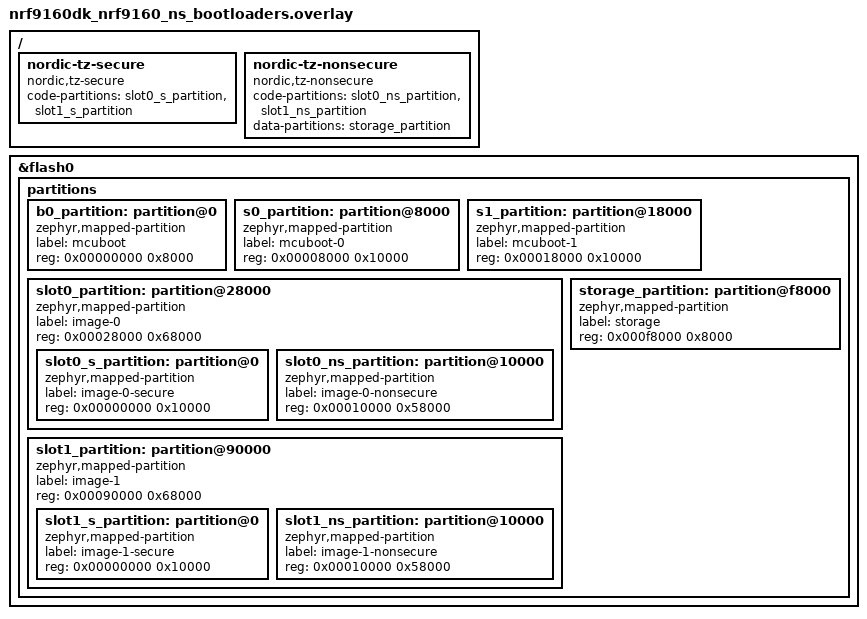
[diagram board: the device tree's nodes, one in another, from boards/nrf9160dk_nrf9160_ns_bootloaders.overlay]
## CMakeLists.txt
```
#
# Copyright (c) 2020 Nordic Semiconductor ASA
#
# SPDX-License-Identifier: LicenseRef-Nordic-5-Clause
#

cmake_minimum_required(VERSION 3.20.0)

find_package(Zephyr REQUIRED HINTS $ENV{ZEPHYR_BASE})

project(tfm_hello_world)

# NORDIC SDK APP START
target_sources(app PRIVATE src/main.c)
# NORDIC SDK APP END
```

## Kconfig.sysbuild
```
#
# Copyright (c) 2026 Nordic Semiconductor
#
# SPDX-License-Identifier: LicenseRef-Nordic-5-Clause
#

config PARTITION_MANAGER
	default n if !SOC_SERIES_NRF91 && !SOC_SERIES_NRF53

source "share/sysbuild/Kconfig"
```

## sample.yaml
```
sample:
  description: Hello World sample, the simplest Zephyr application, with TF-M enabled
  name: TF-M Hello World sample
common:
  tags:
    - tfm
    - ci_samples_tfm
  platform_allow:
    - nrf5340dk/nrf5340/cpuapp/ns
    - nrf9151dk/nrf9151/ns
    - nrf9160dk/nrf9160/ns
    - nrf9161dk/nrf9161/ns
  integration_platforms:
    - nrf5340dk/nrf5340/cpuapp/ns
    - nrf9151dk/nrf9151/ns
    - nrf9160dk/nrf9160/ns
    - nrf9161dk/nrf9161/ns
  harness: console
  harness_config:
    type: multi_line
    regex:
      - ".*Example finished successfully!.*"
tests:
  sample.tfm.helloworld:
    sysbuild: true
    tags:
      - ci_build
      - sysbuild
      - ci_samples_tfm
    platform_allow:
      - nrf54l15dk/nrf54l15/cpuapp/ns
      - nrf54lc10dk/nrf54lc10a/cpuapp/ns
      - nrf54lv10dk/nrf54lv10a/cpuapp/ns
      - nrf54lm20dk/nrf54lm20a/cpuapp/ns
      - nrf54lm20dk/nrf54lm20b/cpuapp/ns
      - nrf7120dk/nrf7120/cpuapp/ns
    integration_platforms:
      - nrf54l15dk/nrf54l15/cpuapp/ns
      - nrf54lc10dk/nrf54lc10a/cpuapp/ns
      - nrf54lv10dk/nrf54lv10a/cpuapp/ns
      - nrf54lm20dk/nrf54lm20a/cpuapp/ns
      - nrf54lm20dk/nrf54lm20b/cpuapp/ns
      - nrf7120dk/nrf7120/cpuapp/ns
  sample.tfm.hello_world.bootloaders:
    sysbuild: true
    tags:
      - ci_build
      - sysbuild
      - ci_samples_tfm
    extra_args: FILE_SUFFIX=bootloaders
  sample.tfm.hello_world.bootloaders_debug:
    sysbuild: true
    build_only: true
    tags:
      - ci_build
      - sysbuild
      - ci_samples_tfm
    extra_args:
      - FILE_SUFFIX=bootloaders
      - CONFIG_DEBUG_OPTIMIZATIONS=y
      - CONFIG_TFM_CMAKE_BUILD_TYPE_MINSIZEREL=y
  sample.tfm.hello_world.full:
    sysbuild: true
    tags:
      - ci_build
      - sysbuild
      - ci_samples_tfm
    extra_args:
      - CONFIG_TFM_PROFILE_TYPE_NOT_SET=y
    platform_allow:
      - nrf54l15dk/nrf54l15/cpuapp/ns
      - nrf54lc10dk/nrf54lc10a/cpuapp/ns
      - nrf54lv10dk/nrf54lv10a/cpuapp/ns
      - nrf54lm20dk/nrf54lm20a/cpuapp/ns
      - nrf54lm20dk/nrf54lm20b/cpuapp/ns
    integration_platforms:
      - nrf54l15dk/nrf54l15/cpuapp/ns
      - nrf54lc10dk/nrf54lc10a/cpuapp/ns
      - nrf54lv10dk/nrf54lv10a/cpuapp/ns
      - nrf54lm20dk/nrf54lm20a/cpuapp/ns
      - nrf54lm20dk/nrf54lm20b/cpuapp/ns
  sample.tfm.hello_world.lvl2:
    sysbuild: true
    tags:
      - ci_build
      - sysbuild
      - ci_samples_tfm
    extra_args:
      - CONFIG_TFM_IPC=y
      - CONFIG_TFM_ISOLATION_LEVEL=2
      - CONFIG_TFM_PROFILE_TYPE_NOT_SET=y
    platform_allow:
      - nrf54l15dk/nrf54l15/cpuapp/ns
      - nrf54lc10dk/nrf54lc10a/cpuapp/ns
      - nrf54lv10dk/nrf54lv10a/cpuapp/ns
      - nrf54lm20dk/nrf54lm20a/cpuapp/ns
      - nrf54lm20dk/nrf54lm20b/cpuapp/ns
    integration_platforms:
      - nrf54l15dk/nrf54l15/cpuapp/ns
      - nrf54lc10dk/nrf54lc10a/cpuapp/ns
      - nrf54lv10dk/nrf54lv10a/cpuapp/ns
      - nrf54lm20dk/nrf54lm20a/cpuapp/ns
      - nrf54lm20dk/nrf54lm20b/cpuapp/ns
```

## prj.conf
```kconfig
#
# Copyright (c) 2020 Nordic Semiconductor ASA
#
# SPDX-License-Identifier: LicenseRef-Nordic-5-Clause
#

CONFIG_TFM_PROFILE_TYPE_MINIMAL=y
CONFIG_PSA_WANT_GENERATE_RANDOM=y
```

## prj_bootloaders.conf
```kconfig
#
# Copyright (c) 2020 Nordic Semiconductor ASA
#
# SPDX-License-Identifier: LicenseRef-Nordic-5-Clause
#

CONFIG_TFM_PROFILE_TYPE_MINIMAL=y
CONFIG_PSA_WANT_GENERATE_RANDOM=y
CONFIG_FW_INFO=y
```

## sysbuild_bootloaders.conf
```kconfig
#
# Copyright (c) 2024 Nordic Semiconductor ASA
#
# SPDX-License-Identifier: LicenseRef-Nordic-5-Clause
#

SB_CONFIG_BOOTLOADER_MCUBOOT=y
SB_CONFIG_SECURE_BOOT_APPCORE=y
# Ineffective here: unsatisfied dependency (!SECURE_BOOT_APPCORE), so
# MCUBOOT_HARDWARE_DOWNGRADE_PREVENTION stays n.
# SB_CONFIG_MCUBOOT_HARDWARE_DOWNGRADE_PREVENTION=y
```

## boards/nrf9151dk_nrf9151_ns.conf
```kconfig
#
# Copyright (c) 2024 Nordic Semiconductor ASA
#
# SPDX-License-Identifier: LicenseRef-Nordic-5-Clause
#

CONFIG_FPU=y
```

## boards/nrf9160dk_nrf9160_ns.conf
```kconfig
#
# Copyright (c) 2022 Nordic Semiconductor ASA
#
# SPDX-License-Identifier: LicenseRef-Nordic-5-Clause
#

CONFIG_FPU=y
```

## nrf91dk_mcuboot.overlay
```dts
/*
 * Copyright (c) 2026 Nordic Semiconductor ASA
 *
 * SPDX-License-Identifier: LicenseRef-Nordic-5-Clause
 */

#include <common/nordic/nrf91_partitions_full_tfm_mcuboot.dtsi>
```

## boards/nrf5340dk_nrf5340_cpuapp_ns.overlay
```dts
/*
 * Copyright (c) 2026 Nordic Semiconductor
 *
 * SPDX-License-Identifier: LicenseRef-Nordic-5-Clause
 */

/delete-node/ &boot_partition;
/delete-node/ &slot0_partition;
/delete-node/ &slot1_partition;
/delete-node/ &storage_partition;

/delete-node/ &tfm_its_partition;
/delete-node/ &tfm_otp_partition;
/delete-node/ &tfm_ps_partition;

&flash0 {
	partitions {
		/* Sized to accommodate the full TF-M profile (selected by
		 * CONFIG_TFM_PROFILE_TYPE_NOT_SET=y in the .full / .lvl2 test
		 * variants), matching the slot0_s split used by
		 * tfm_secure_peripheral. The minimal profile used by the
		 * default and bootloaders builds easily fits in this region.
		 */
		slot0_s_partition: partition@0 {
			compatible = "zephyr,mapped-partition";
			label = "image-0-secure";
			reg = <0x0 0x40000>;
		};

		slot0_ns_partition: partition@40000 {
			compatible = "zephyr,mapped-partition";
			label = "image-0-nonsecure";
			reg = <0x40000 0xb4000>;
		};

		/* TF-M storage region for the full / lvl2 profiles. The
		 * minimal profile used by the default and bootloaders builds
		 * does not consume these partitions, so they only cost flash
		 * when CONFIG_TFM_PROFILE_TYPE_NOT_SET=y selects a profile
		 * with PS/ITS/OTP enabled.
		 */
		tfm_storage_partition: partition@f4000 {
			compatible = "zephyr,mapped-partition";
			label = "tfm-storage";
			reg = <0xf4000 DT_SIZE_K(48)>;
			ranges = <0x0 0xf4000 DT_SIZE_K(48)>;
			#address-cells = <1>;
			#size-cells = <1>;

			tfm_its_partition: partition@0 {
				compatible = "zephyr,mapped-partition";
				label = "tfm-its";
				reg = <0x0 DT_SIZE_K(8)>;
			};

			tfm_otp_partition: partition@4000 {
				compatible = "zephyr,mapped-partition";
				label = "tfm-otp";
				reg = <0x4000 DT_SIZE_K(8)>;
			};

			tfm_ps_partition: partition@8000 {
				compatible = "zephyr,mapped-partition";
				label = "tfm-ps";
				reg = <0x8000 DT_SIZE_K(16)>;
			};
		};
	};
};

/ {
	/delete-node/ nordic-tz-secure;
	/delete-node/ nordic-tz-nonsecure;

	nordic-tz-secure {
		compatible = "nordic,tz-secure";
		code-partitions = <&slot0_s_partition>;
		data-partitions = <&tfm_ps_partition>,
				  <&tfm_its_partition>,
				  <&tfm_otp_partition>;
	};

	nordic-tz-nonsecure {
		compatible = "nordic,tz-nonsecure";
		code-partitions = <&slot0_ns_partition>;
	};
};
```

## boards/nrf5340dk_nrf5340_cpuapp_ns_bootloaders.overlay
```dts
/*
 * Copyright (c) 2026 Nordic Semiconductor ASA
 *
 * SPDX-License-Identifier: LicenseRef-Nordic-5-Clause
 *
 * NS-application partition layout for the bootloaders variant of this sample
 * (selected by FILE_SUFFIX=bootloaders). Shares the b0 / MCUboot flash
 * layout with the mcuboot and b0 images via the included .dtsi, then nests
 * the TF-M secure / non-secure split inside MCUboot's image-0 slot.
 */

#include "../dts/nrf5340_bootloaders_partitions.dtsi"

/delete-node/ &tfm_its_partition;
/delete-node/ &tfm_otp_partition;
/delete-node/ &tfm_ps_partition;

&slot0_partition {
	ranges = <0x0 0x28000 0x68000>;
	#address-cells = <1>;
	#size-cells = <1>;

	slot0_s_partition: partition@0 {
		compatible = "zephyr,mapped-partition";
		label = "image-0-secure";
		reg = <0x0 0x40000>;
	};

	slot0_ns_partition: partition@40000 {
		compatible = "zephyr,mapped-partition";
		label = "image-0-nonsecure";
		reg = <0x40000 0x28000>;
	};
};

/ {
	/delete-node/ nordic-tz-secure;
	/delete-node/ nordic-tz-nonsecure;

	nordic-tz-secure {
		compatible = "nordic,tz-secure";
		code-partitions = <&slot0_s_partition>;
	};

	nordic-tz-nonsecure {
		compatible = "nordic,tz-nonsecure";
		code-partitions = <&slot0_ns_partition>;
	};
};
```

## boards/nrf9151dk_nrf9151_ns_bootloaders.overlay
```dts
/*
 * Copyright (c) 2026 Nordic Semiconductor ASA
 *
 * SPDX-License-Identifier: LicenseRef-Nordic-5-Clause
 */

/* Set custom partition table to allow both bootloaders and TFM with debugging */
/delete-node/ &boot_partition;
/delete-node/ &slot0_partition;
/delete-node/ &slot1_partition;
/delete-node/ &tfm_ps_partition;
/delete-node/ &tfm_its_partition;
/delete-node/ &tfm_otp_partition;
/delete-node/ &storage_partition;

&flash0 {
	/*
	 * 0x0000_0000  B0 (NSIB)                    ( 32 kB)
	 * 0x0000_8000  Primary updatable MCUboot    ( 64 kB)
	 * 0x0001_8000  Secondary updatable MCUboot  ( 64 kB)
	 * 0x0002_8000  Primary image area           (416 kB)
	 *   0x0002_8000  Primary secure image       ( 64 kB)
	 *   0x0003_8000  Primary non-secure image   (352 kB)
	 * 0x0009_0000  Secondary image area         (416 kB)
	 *   0x0009_0000  Secondary secure image     ( 64 kB)
	 *   0x000a_0000  Secondary non-secure image (352 kB)
	 * 0x000f_8000  Settings storage             ( 32 kB)
	 */

	partitions {
		ranges;
		#address-cells = <1>;
		#size-cells = <1>;

		b0_partition: partition@0 {
			compatible = "zephyr,mapped-partition";
			label = "mcuboot";
			reg = <0x00000000 0x8000>;
		};

		s0_partition: partition@8000 {
			compatible = "zephyr,mapped-partition";
			label = "mcuboot-0";
			reg = <0x00008000 0x10000>;
		};

		s1_partition: partition@18000 {
			compatible = "zephyr,mapped-partition";
			label = "mcuboot-1";
			reg = <0x00018000 0x10000>;
		};

		slot0_partition: partition@28000 {
			compatible = "zephyr,mapped-partition";
			label = "image-0";
			reg = <0x00028000 0x68000>;
			ranges = <0x0 0x00028000 0x68000>;
			#address-cells = <1>;
			#size-cells = <1>;

			slot0_s_partition: partition@0 {
				compatible = "zephyr,mapped-partition";
				label = "image-0-secure";
				reg = <0x00000000 0x10000>;
			};

			slot0_ns_partition: partition@10000 {
				compatible = "zephyr,mapped-partition";
				label = "image-0-nonsecure";
				reg = <0x00010000 0x58000>;
			};
		};

		slot1_partition: partition@90000 {
			compatible = "zephyr,mapped-partition";
			label = "image-1";
			reg = <0x00090000 0x68000>;
			ranges = <0x0 0x00090000 0x68000>;
			#address-cells = <1>;
			#size-cells = <1>;

			slot1_s_partition: partition@0 {
				compatible = "zephyr,mapped-partition";
				label = "image-1-secure";
				reg = <0x00000000 0x10000>;
			};

			slot1_ns_partition: partition@10000 {
				compatible = "zephyr,mapped-partition";
				label = "image-1-nonsecure";
				reg = <0x00010000 0x58000>;
			};
		};

		storage_partition: partition@f8000 {
			compatible = "zephyr,mapped-partition";
			label = "storage";
			reg = <0x000f8000 0x8000>;
		};
	};
};

#include <samples/cellular/nrf91_sram_partitions.dtsi>

/*
 * This layout redefines the flash partition map, dropping partitions that the
 * upstream nordic-tz-secure/-nonsecure descriptors reference. Remove the
 * descriptors so they do not hold dangling phandles (restores the behaviour
 * from before the descriptors were introduced).
 */
/ {
	/delete-node/ nordic-tz-secure;
	/delete-node/ nordic-tz-nonsecure;
};
```

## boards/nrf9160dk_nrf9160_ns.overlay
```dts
/*
 * Copyright (c) 2026 Nordic Semiconductor ASA
 *
 * SPDX-License-Identifier: LicenseRef-Nordic-5-Clause
 */

#include <samples/cellular/nrf91_crypto_partitions.dtsi>

#include <samples/cellular/nrf91_sram_crypto_partitions.dtsi>
```

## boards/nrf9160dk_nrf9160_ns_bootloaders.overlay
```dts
/*
 * Copyright (c) 2026 Nordic Semiconductor ASA
 *
 * SPDX-License-Identifier: LicenseRef-Nordic-5-Clause
 */

/* Set custom partition table to allow both bootloaders and TFM with debugging */
/delete-node/ &boot_partition;
/delete-node/ &slot0_partition;
/delete-node/ &slot1_partition;
/delete-node/ &tfm_ps_partition;
/delete-node/ &tfm_its_partition;
/delete-node/ &tfm_otp_partition;
/delete-node/ &storage_partition;

&flash0 {
	/*
	 * 0x0000_0000  B0 (NSIB)                    ( 32 kB)
	 * 0x0000_8000  Primary updatable MCUboot    ( 64 kB)
	 * 0x0001_8000  Secondary updatable MCUboot  ( 64 kB)
	 * 0x0002_8000  Primary image area           (416 kB)
	 *   0x0002_8000  Primary secure image       ( 64 kB)
	 *   0x0003_8000  Primary non-secure image   (352 kB)
	 * 0x0009_0000  Secondary image area         (416 kB)
	 *   0x0009_0000  Secondary secure image     ( 64 kB)
	 *   0x000a_0000  Secondary non-secure image (352 kB)
	 * 0x000f_8000  Settings storage             ( 32 kB)
	 */

	partitions {
		ranges;
		#address-cells = <1>;
		#size-cells = <1>;

		b0_partition: partition@0 {
			compatible = "zephyr,mapped-partition";
			label = "mcuboot";
			reg = <0x00000000 0x8000>;
		};

		s0_partition: partition@8000 {
			compatible = "zephyr,mapped-partition";
			label = "mcuboot-0";
			reg = <0x00008000 0x10000>;
		};

		s1_partition: partition@18000 {
			compatible = "zephyr,mapped-partition";
			label = "mcuboot-1";
			reg = <0x00018000 0x10000>;
		};

		slot0_partition: partition@28000 {
			compatible = "zephyr,mapped-partition";
			label = "image-0";
			reg = <0x00028000 0x68000>;
			ranges = <0x0 0x00028000 0x68000>;
			#address-cells = <1>;
			#size-cells = <1>;

			slot0_s_partition: partition@0 {
				compatible = "zephyr,mapped-partition";
				label = "image-0-secure";
				reg = <0x00000000 0x10000>;
			};

			slot0_ns_partition: partition@10000 {
				compatible = "zephyr,mapped-partition";
				label = "image-0-nonsecure";
				reg = <0x00010000 0x58000>;
			};
		};

		slot1_partition: partition@90000 {
			compatible = "zephyr,mapped-partition";
			label = "image-1";
			reg = <0x00090000 0x68000>;
			ranges = <0x0 0x00090000 0x68000>;
			#address-cells = <1>;
			#size-cells = <1>;

			slot1_s_partition: partition@0 {
				compatible = "zephyr,mapped-partition";
				label = "image-1-secure";
				reg = <0x00000000 0x10000>;
			};

			slot1_ns_partition: partition@10000 {
				compatible = "zephyr,mapped-partition";
				label = "image-1-nonsecure";
				reg = <0x00010000 0x58000>;
			};
		};

		storage_partition: partition@f8000 {
			compatible = "zephyr,mapped-partition";
			label = "storage";
			reg = <0x000f8000 0x8000>;
		};
	};
};

#include <samples/cellular/nrf91_sram_partitions.dtsi>

/ {
	/delete-node/ nordic-tz-secure;
	/delete-node/ nordic-tz-nonsecure;

	nordic-tz-secure {
		compatible = "nordic,tz-secure";
		code-partitions = <&slot0_s_partition>,
				  <&slot1_s_partition>;
	};

	nordic-tz-nonsecure {
		compatible = "nordic,tz-nonsecure";
		code-partitions = <&slot0_ns_partition>,
				  <&slot1_ns_partition>;
		data-partitions = <&storage_partition>;
	};
};
```

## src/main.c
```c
/*
 * Copyright (c) 2020 Nordic Semiconductor ASA.
 *
 * SPDX-License-Identifier: LicenseRef-Nordic-5-Clause
 */

#include <zephyr/kernel.h>
#include <zephyr/devicetree.h>
#include <zephyr/sys/printk.h>
#include <string.h>
#include <stdio.h>
#include <tfm_ns_interface.h>
#include "psa/crypto.h"
#ifdef CONFIG_TFM_PARTITION_PLATFORM
#include <tfm_ioctl_api.h>
#endif
#include <hal/nrf_gpio.h>

#define HELLO_PATTERN "Hello World! %s"

/*
 * The samples require a timer mapped as non-secure:
 * For nRF91 and nRF53 TIMER1 can be mapped as non-secure
 * For nRF54L TIMER1 doesn't exist so we use TIMER00 instead
 */
#if defined(NRF_TIMER1_NS)
#define SAMPLE_NS_TIMER NRF_TIMER1_NS
#elif defined(NRF_TIMER00_NS)
#define SAMPLE_NS_TIMER NRF_TIMER00_NS
#else
#endif

#if defined(CONFIG_TFM_PARTITION_PLATFORM)

static uint32_t secure_read_word(intptr_t ptr)
{
	uint32_t err = 0;
	uint32_t val;
	enum tfm_platform_err_t plt_err;

	plt_err = tfm_platform_mem_read(&val, ptr, 4, &err);
	if (plt_err != TFM_PLATFORM_ERR_SUCCESS || err != 0) {
		printk("tfm_..._mem_read failed: plt_err: 0x%x, err: 0x%x\n",
			plt_err, err);
		return -1;
	}

	return val;
}

#if defined(NRF_FICR_S)
void demonstrate_secure_memory_access(void)
{
	uint32_t info_ram;

	SAMPLE_NS_TIMER->TASKS_START = 1;
	info_ram = secure_read_word((intptr_t)&NRF_FICR_S->INFO.RAM);
	SAMPLE_NS_TIMER->TASKS_CAPTURE[0] = 1;
	printk("Approximate IPC overhead us: %d\n", SAMPLE_NS_TIMER->CC[0]);

	printk("FICR->INFO.FLASH: 0x%08x\n",
		secure_read_word((intptr_t)&NRF_FICR_S->INFO.FLASH));
}
#elif defined(NRF_APPLICATION_CPUC_S)
void demonstrate_secure_memory_access(void)
{
	uint32_t cpu_id;

	SAMPLE_NS_TIMER->TASKS_START = 1;
	cpu_id = secure_read_word((intptr_t)&NRF_APPLICATION_CPUC_S->CPUID);
	SAMPLE_NS_TIMER->TASKS_CAPTURE[0] = 1;
	printk("Approximate IPC overhead us: %d\n", SAMPLE_NS_TIMER->CC[0]);
	printk("NRF_APPLICATION_CPUC_S->CPUID: 0x%08x\n", cpu_id);
}
#else
#error "The samples requires either FICR or the CPUC peripheral mapped as \
	secure to demonstrate secure memory access"
#endif

#endif /* defined(CONFIG_TFM_PARTITION_PLATFORM) */

static void print_hex_number(uint8_t *num, size_t len)
{
	printk("0x");
	for (int i = 0; i < len; i++) {
		printk("%02x", num[i]);
	}
	printk("\n");
}

int main(void)
{
	bool failed = false;
	char hello_string[sizeof(HELLO_PATTERN) + sizeof(CONFIG_BOARD_TARGET)];
	size_t len;

	len = snprintf(hello_string, sizeof(hello_string),
		HELLO_PATTERN, CONFIG_BOARD_TARGET);

	printk("%s\n", hello_string);

#if defined(CONFIG_TFM_PARTITION_PLATFORM)
	printk("Reading some secure memory that NS is allowed to read\n");
	demonstrate_secure_memory_access();

#endif /* defined(CONFIG_TFM_PARTITION_PLATFORM) */

	if (IS_ENABLED(CONFIG_TFM_CRYPTO_RNG_MODULE_ENABLED)) {
		psa_status_t status;
		uint8_t random_bytes[32];

		printk("Generating random number\n");
		status = psa_generate_random(random_bytes, sizeof(random_bytes));
		if (status != PSA_SUCCESS) {
			printk("psa_generate_random failed with status %d\n", status);
			failed = true;
		} else {
			print_hex_number(random_bytes, sizeof(random_bytes));
		}
	}

	if (IS_ENABLED(CONFIG_TFM_CRYPTO_HASH_MODULE_ENABLED)) {
		psa_status_t status;
		char hello_digest[32];

		printk("Hashing '%s'\n", hello_string);
		status = psa_crypto_init();
		if (status != PSA_SUCCESS) {
			printk("psa_crypto_init failed with status %d\n", status);
			failed = true;
		}
		status = psa_hash_compute(PSA_ALG_SHA_256, hello_string,
						strlen(hello_string), hello_digest,
						sizeof(hello_digest), &len);

		if (status != PSA_SUCCESS) {
			printk("psa_hash_compute failed with status %d\n", status);
			failed = true;
		} else {
			printk("SHA256 digest:\n");
			print_hex_number(hello_digest, 32);
		}
	}

#if defined(CONFIG_TFM_PARTITION_PLATFORM)
#if DT_NODE_EXISTS(DT_NODELABEL(s0_partition)) && DT_NODE_EXISTS(DT_NODELABEL(s1_partition))
	bool s0_active = false;
	int ret;

	ret = tfm_platform_s0_active(DT_REG_ADDR(DT_NODELABEL(s0_partition)),
				     DT_REG_ADDR(DT_NODELABEL(s1_partition)), &s0_active);
	if (ret != 0) {
		printk("Unexpected failure from tfm_platform_s0_active: %d\n", ret);
		failed = true;
	}

	printk("S0 active? %s\n", s0_active ? "True" : "False");
#endif /* s0_partition && s1_partition */
#endif /* defined(CONFIG_TFM_PARTITION_PLATFORM) */

	if (!failed) {
		printk("Example finished successfully!\n");
	}

	return failed;
}
```
